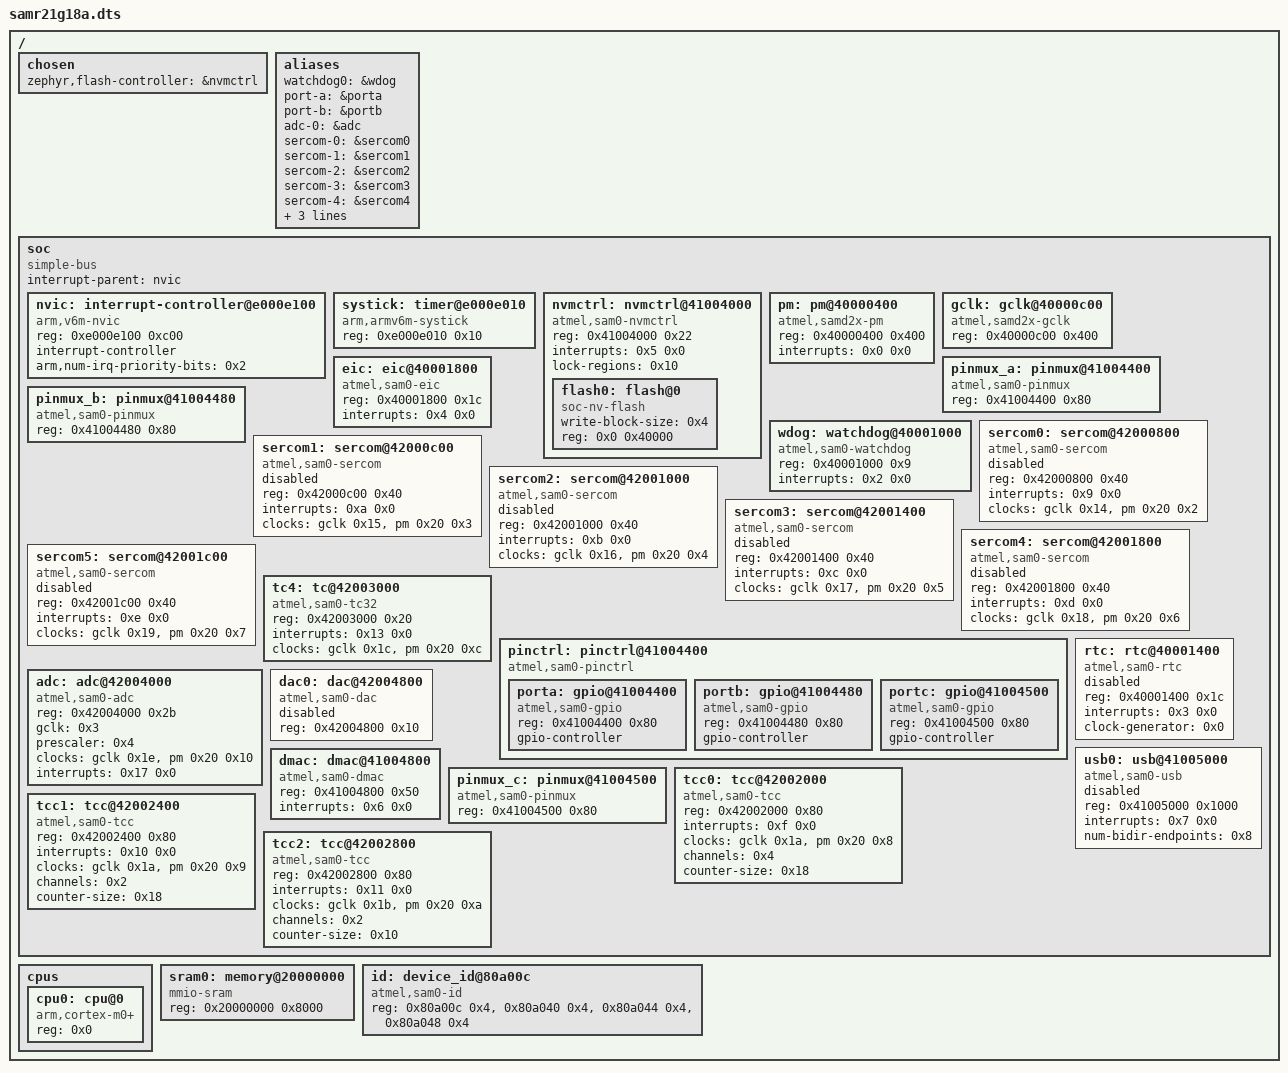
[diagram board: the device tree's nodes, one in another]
/dts-v1/;

/ {
	#address-cells = < 0x1 >;
	#size-cells = < 0x1 >;
	chosen {
		zephyr,flash-controller = &nvmctrl;
	};
	aliases {
		watchdog0 = &wdog;
		port-a = &porta;
		port-b = &portb;
		adc-0 = &adc;
		sercom-0 = &sercom0;
		sercom-1 = &sercom1;
		sercom-2 = &sercom2;
		sercom-3 = &sercom3;
		sercom-4 = &sercom4;
		sercom-5 = &sercom5;
		tc-4 = &tc4;
		port-c = &portc;
	};
	soc {
		#address-cells = < 0x1 >;
		#size-cells = < 0x1 >;
		compatible = "simple-bus";
		interrupt-parent = < &nvic >;
		ranges;
		nvic: interrupt-controller@e000e100 {
			#address-cells = < 0x1 >;
			compatible = "arm,v6m-nvic";
			reg = < 0xe000e100 0xc00 >;
			interrupt-controller;
			#interrupt-cells = < 0x2 >;
			arm,num-irq-priority-bits = < 0x2 >;
			phandle = < 0x1 >;
		};
		systick: timer@e000e010 {
			compatible = "arm,armv6m-systick";
			reg = < 0xe000e010 0x10 >;
		};
		nvmctrl: nvmctrl@41004000 {
			compatible = "atmel,sam0-nvmctrl";
			reg = < 0x41004000 0x22 >;
			interrupts = < 0x5 0x0 >;
			lock-regions = < 0x10 >;
			#address-cells = < 0x1 >;
			#size-cells = < 0x1 >;
			flash0: flash@0 {
				compatible = "soc-nv-flash";
				write-block-size = < 0x4 >;
				reg = < 0x0 0x40000 >;
			};
		};
		pm: pm@40000400 {
			compatible = "atmel,samd2x-pm";
			reg = < 0x40000400 0x400 >;
			interrupts = < 0x0 0x0 >;
			#clock-cells = < 0x2 >;
			phandle = < 0x3 >;
		};
		gclk: gclk@40000c00 {
			compatible = "atmel,samd2x-gclk";
			reg = < 0x40000c00 0x400 >;
			#clock-cells = < 0x1 >;
			phandle = < 0x2 >;
		};
		eic: eic@40001800 {
			compatible = "atmel,sam0-eic";
			reg = < 0x40001800 0x1c >;
			interrupts = < 0x4 0x0 >;
		};
		pinmux_a: pinmux@41004400 {
			compatible = "atmel,sam0-pinmux";
			reg = < 0x41004400 0x80 >;
		};
		pinmux_b: pinmux@41004480 {
			compatible = "atmel,sam0-pinmux";
			reg = < 0x41004480 0x80 >;
		};
		wdog: watchdog@40001000 {
			compatible = "atmel,sam0-watchdog";
			reg = < 0x40001000 0x9 >;
			interrupts = < 0x2 0x0 >;
		};
		sercom0: sercom@42000800 {
			compatible = "atmel,sam0-sercom";
			reg = < 0x42000800 0x40 >;
			status = "disabled";
			interrupts = < 0x9 0x0 >;
			clocks = < &gclk 0x14 >, < &pm 0x20 0x2 >;
			clock-names = "GCLK", "PM";
		};
		sercom1: sercom@42000c00 {
			compatible = "atmel,sam0-sercom";
			reg = < 0x42000c00 0x40 >;
			status = "disabled";
			interrupts = < 0xa 0x0 >;
			clocks = < &gclk 0x15 >, < &pm 0x20 0x3 >;
			clock-names = "GCLK", "PM";
		};
		sercom2: sercom@42001000 {
			compatible = "atmel,sam0-sercom";
			reg = < 0x42001000 0x40 >;
			status = "disabled";
			interrupts = < 0xb 0x0 >;
			clocks = < &gclk 0x16 >, < &pm 0x20 0x4 >;
			clock-names = "GCLK", "PM";
		};
		sercom3: sercom@42001400 {
			compatible = "atmel,sam0-sercom";
			reg = < 0x42001400 0x40 >;
			status = "disabled";
			interrupts = < 0xc 0x0 >;
			clocks = < &gclk 0x17 >, < &pm 0x20 0x5 >;
			clock-names = "GCLK", "PM";
		};
		sercom4: sercom@42001800 {
			compatible = "atmel,sam0-sercom";
			reg = < 0x42001800 0x40 >;
			status = "disabled";
			interrupts = < 0xd 0x0 >;
			clocks = < &gclk 0x18 >, < &pm 0x20 0x6 >;
			clock-names = "GCLK", "PM";
		};
		sercom5: sercom@42001c00 {
			compatible = "atmel,sam0-sercom";
			reg = < 0x42001c00 0x40 >;
			status = "disabled";
			interrupts = < 0xe 0x0 >;
			clocks = < &gclk 0x19 >, < &pm 0x20 0x7 >;
			clock-names = "GCLK", "PM";
		};
		tc4: tc@42003000 {
			compatible = "atmel,sam0-tc32";
			reg = < 0x42003000 0x20 >;
			interrupts = < 0x13 0x0 >;
			clocks = < &gclk 0x1c >, < &pm 0x20 0xc >;
			clock-names = "GCLK", "PM";
		};
		pinctrl: pinctrl@41004400 {
			compatible = "atmel,sam0-pinctrl";
			#address-cells = < 0x1 >;
			#size-cells = < 0x1 >;
			ranges = < 0x41004400 0x41004400 0x180 >;
			porta: gpio@41004400 {
				compatible = "atmel,sam0-gpio";
				reg = < 0x41004400 0x80 >;
				gpio-controller;
				#gpio-cells = < 0x2 >;
				#atmel,pin-cells = < 0x2 >;
			};
			portb: gpio@41004480 {
				compatible = "atmel,sam0-gpio";
				reg = < 0x41004480 0x80 >;
				gpio-controller;
				#gpio-cells = < 0x2 >;
				#atmel,pin-cells = < 0x2 >;
			};
			portc: gpio@41004500 {
				compatible = "atmel,sam0-gpio";
				reg = < 0x41004500 0x80 >;
				gpio-controller;
				#gpio-cells = < 0x2 >;
				#atmel,pin-cells = < 0x2 >;
			};
		};
		rtc: rtc@40001400 {
			compatible = "atmel,sam0-rtc";
			reg = < 0x40001400 0x1c >;
			interrupts = < 0x3 0x0 >;
			clock-generator = < 0x0 >;
			status = "disabled";
		};
		adc: adc@42004000 {
			compatible = "atmel,sam0-adc";
			reg = < 0x42004000 0x2b >;
			gclk = < 0x3 >;
			prescaler = < 0x4 >;
			#io-channel-cells = < 0x1 >;
			clocks = < &gclk 0x1e >, < &pm 0x20 0x10 >;
			clock-names = "GCLK", "PM";
			interrupts = < 0x17 0x0 >;
			interrupt-names = "resrdy";
		};
		dac0: dac@42004800 {
			compatible = "atmel,sam0-dac";
			status = "disabled";
			reg = < 0x42004800 0x10 >;
			#io-channel-cells = < 0x0 >;
		};
		usb0: usb@41005000 {
			compatible = "atmel,sam0-usb";
			status = "disabled";
			reg = < 0x41005000 0x1000 >;
			interrupts = < 0x7 0x0 >;
			num-bidir-endpoints = < 0x8 >;
		};
		dmac: dmac@41004800 {
			compatible = "atmel,sam0-dmac";
			reg = < 0x41004800 0x50 >;
			interrupts = < 0x6 0x0 >;
			#dma-cells = < 0x2 >;
		};
		pinmux_c: pinmux@41004500 {
			compatible = "atmel,sam0-pinmux";
			reg = < 0x41004500 0x80 >;
		};
		tcc0: tcc@42002000 {
			compatible = "atmel,sam0-tcc";
			reg = < 0x42002000 0x80 >;
			interrupts = < 0xf 0x0 >;
			clocks = < &gclk 0x1a >, < &pm 0x20 0x8 >;
			clock-names = "GCLK", "PM";
			channels = < 0x4 >;
			counter-size = < 0x18 >;
		};
		tcc1: tcc@42002400 {
			compatible = "atmel,sam0-tcc";
			reg = < 0x42002400 0x80 >;
			interrupts = < 0x10 0x0 >;
			clocks = < &gclk 0x1a >, < &pm 0x20 0x9 >;
			clock-names = "GCLK", "PM";
			channels = < 0x2 >;
			counter-size = < 0x18 >;
		};
		tcc2: tcc@42002800 {
			compatible = "atmel,sam0-tcc";
			reg = < 0x42002800 0x80 >;
			interrupts = < 0x11 0x0 >;
			clocks = < &gclk 0x1b >, < &pm 0x20 0xa >;
			clock-names = "GCLK", "PM";
			channels = < 0x2 >;
			counter-size = < 0x10 >;
		};
	};
	cpus {
		#address-cells = < 0x1 >;
		#size-cells = < 0x0 >;
		cpu0: cpu@0 {
			device_type = "cpu";
			compatible = "arm,cortex-m0+";
			reg = < 0x0 >;
		};
	};
	sram0: memory@20000000 {
		compatible = "mmio-sram";
		reg = < 0x20000000 0x8000 >;
	};
	id: device_id@80a00c {
		compatible = "atmel,sam0-id";
		reg = < 0x80a00c 0x4 >, < 0x80a040 0x4 >, < 0x80a044 0x4 >, < 0x80a048 0x4 >;
	};
};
